# SN32F400 register map
Vendor: SONiX Technology Co., Ltd.; Series: SN32F400; File version: 1.1
CPU: CM0 r0p0, little endian, no MPU, no FPU, 2 interrupt priority bits
Registers are 32-bit, read-write, reset 0x0 unless marked. A register's access mark holds for its fields unless they carry their own. Offsets are from the block's base; [hi:lo] are bit positions; {n}, {i} and the like mark numbered series.

## SN_SPI0 — SPI0
Base 0x4001C000
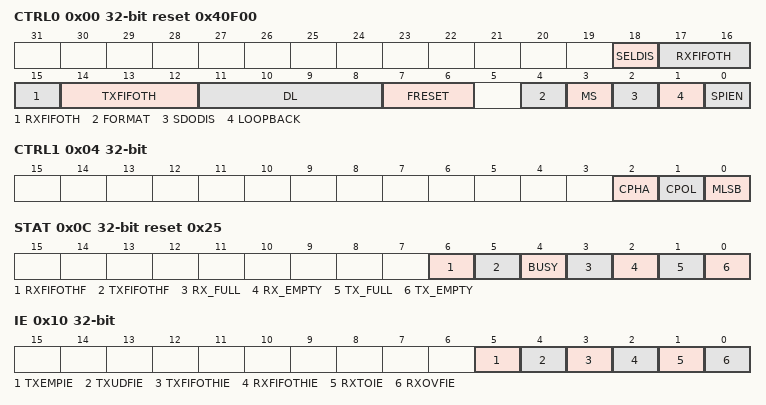
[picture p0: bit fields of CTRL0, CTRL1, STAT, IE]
0x00 CTRL0 reset 0x40F00 — Offset:0x00 SPIn Control register 0
  [18] SELDIS — Auto-SEL disable bit
    0=Enable Auto-SEL flow control; 1=Disable Auto-SEL flow control
  [17:15] RXFIFOTH — RX FIFO Threshold level
    {v}=LV{v} (RX FIFO threshold level is {v}) (v=0..7)
  [14:12] TXFIFOTH — TX FIFO Threshold level
    {v}=LV{v} (TX FIFO threshold level is {v}) (v=0..7)
  [11:8] DL — Data length = DL[3:0]+1
    {v}=Data length={v+1} (v=2..15)
  [7:6] FRESET wo — SPI FSM and FIFO Reset
    0=No effect; 3=Reset FSM and FIFO
  [4] FORMAT — Interface format
    0=SPI (SPI format)
  [3] MS — Master/Slave selection
    0=Master (Act as Master); 1=Slave (Act as Slave)
  [2] SDODIS — Slave data out disable
    0=Enable slave data out; 1=Disable (Diable slave data out (MISO=0))
  [1] LOOPBACK — Loopback mode enable
    0=Disable loopback mode; 1=Enable loopback mode
  [0] SPIEN — SPI enable
    0=Disable SPI; 1=Enable SPI
0x04 CTRL1 — Offset:0x04 SPIn Control register 1
  [2] CPHA — Clock phase of edge sampling
    0=The 1st bit is fixed already, and SCK 1st edge is to receive/transmit data; 1=SCK 1st edge is for data transition, and receive/transmit data at 2nd edge
  [1] CPOL — Clock priority selection
    0=Low (SCK idles at low level); 1=High (SCK idles at high level)
  [0] MLSB — MSB/LSB seletion
    0=MSB (MSB transmit first); 1=LSB (LSB transmit first)
0x08 CLKDIV — Offset:0x08 SPIn Clock Divider register
  [7:0] DIV — SPI0 SCK
0x0C STAT ro reset 0x25 — Offset:0x0C SPIn Status register
  [6] RXFIFOTHF — RX FIFO threshold flag
    0=Less equal (Data count in RX FIFO is less equal than RXFIFOTH); 1=More (Data count in RX FIFO is larger than RXFIFOTH)
  [5] TXFIFOTHF — TX FIFO threshold flag
    0=More (Data count in TX FIFO is larger than TXFIFOTH); 1=Less equal (Data count in TX FIFO is less equal than TXFIFOTH)
  [4] BUSY — Busy flag
    0=Idle (SSPn is idle); 1=Busy (SSPn is transfering)
  [3] RX_FULL — RX FIFO full flag
    0=None (RX FIFO is not full); 1=Full (RX FIFO is full)
  [2] RX_EMPTY — RX FIFO empty flag
    0=None (RX FIFO is not empty); 1=Empty (RX FIFO is empty)
  [1] TX_FULL — TX FIFO full flag
    0=None (TX FIFO is not full); 1=Full (TX FIFO is full)
  [0] TX_EMPTY — TX FIFO empty flag
    0=None (TX FIFO is not empty); 1=Empty (TX FIFO is empty)
0x10 IE — Offset:0x10 SPIn Interrupt Enable register
  [5] TXEMPIE — TX all empty interrupt enable
    0=Disable TX all empty interrupt; 1=Enable TX all empty interrupt
  [4] TXUDFIE — TX underflow interrupt enable
    0=Disable TX underflow interrupt; 1=Enable TX underflow interrupt
  [3] TXFIFOTHIE — TX FIFO threshold interrupt enable
    0=Disable TX FIFO threshold interrupt; 1=Enable TX FIFO threshold interrupt
  [2] RXFIFOTHIE — RX FIFO threshold interrupt enable
    0=Disable RX FIFO threshold interrupt; 1=Enable RX FIFO threshold interrupt
  [1] RXTOIE — RX time-out interrupt enable
    0=Disable RX time-out interrupt; 1=Enable RX time-out interrupt
  [0] RXOVFIE — RX FIFO overflow interrupt enable
    0=Disable RX FIFO overflow interrupt; 1=Enable RX FIFO overflow interrupt
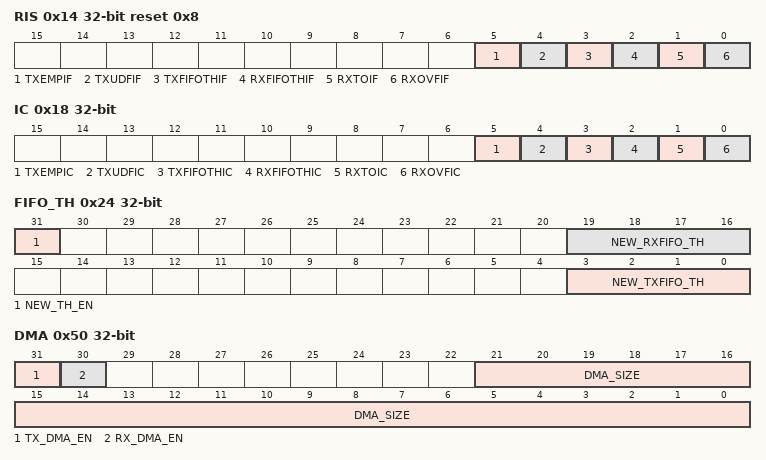
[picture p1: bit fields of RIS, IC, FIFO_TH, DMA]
0x14 RIS ro reset 0x8 — Offset:0x14 SPIn Raw Interrupt Status register
  [5] TXEMPIF — TX all empty interrupt flag
    0=No (No TX all empty interrupt); 1=All empty (TX all empty triggered)
  [4] TXUDFIF — TX underflow interrupt flag
    0=No (No TX underflow interrupt); 1=Underflow (TX underflow triggered)
  [3] TXFIFOTHIF — TX FIFO threshold interrupt flag
    0=No (No TXFIFOTH interrupt); 1=Met (TX FIFO threshold is triggered when TXFIFOTHIE=1)
  [2] RXFIFOTHIF — RX FIFO threshold interrupt flag
    0=No (No RXFIFOTH interrupt); 1=Met (RX FIFO threshold is triggered when RXFIFOTHIE=1)
  [1] RXTOIF — RX time-out interrupt flag
    0=No (No RXTO interrupt); 1=Met (RXTO interrupt is triggered when RXTOIE=1)
  [0] RXOVFIF — RX FIFO overflow interrupt flag
    0=No (No RXOVF interrupt); 1=Met (RXOVF interrupt is triggered when RXOVFIE=1)
0x18 IC wo — Offset:0x18 SPIn Interrupt Clear register
  [5] TXEMPIC — TX empty interrupt flag Clear
    0=None (No effect); 1=Clear TXEMPIF flag
  [4] TXUDFIC — TX underflow interrupt flag Clear
    0=None (No effect); 1=Clear TXUDIF flag
  [3] TXFIFOTHIC — TX Interrupt flag Clear
    0=None (No effect); 1=Clear TXFIFOTH flag
  [2] RXFIFOTHIC — RX Interrupt flag Clear
    0=None (No effect); 1=Clear RXFIFOTH flag
  [1] RXTOIC — RX time-out interrupt flag clear
    0=None (No effect); 1=Clear RXTO flag
  [0] RXOVFIC — RX FIFO overflow flag clear
    0=None (No effect); 1=Clear RXOVF flag
0x1C DATA — Offset:0x1C SPIn Data register
  [15:0] DATA — SPI Data
0x20 DFDLY — Offset:0x20 SPIn Data Fetch register
  [0] DF — SPI0 data fetch control bit
    0=Disable data fetch delay function; 1=Enable when SCKn frequency is higher than 6MHz
0x24 FIFO_TH — Offset:0x24 SPIn FIFO threshold register
  [31] NEW_TH_EN — Use new TX/RX threshold setting
    0=FIFO 8*half-word (TX/RX threshold setting is from TX/RXFIFOTH[2:0]); 1=FIFO 16*byte (TX/RX threshold setting is from NEW_TX/RXFIFO_TH[3:0])
  [19:16] NEW_RXFIFO_TH — RX FIFO Threshold level
  [3:0] NEW_TXFIFO_TH — TX FIFO Threshold level
0x50 DMA — Offset:0x50 SPIn DMA mode register
  [31] TX_DMA_EN — TX DMA enable
    0=Disable TX DMA mode; 1=Enable TX DMA mode
  [30] RX_DMA_EN — RX DMA enable
    0=Disable RX DMA mode; 1=Enable RX DMA mode
  [21:0] DMA_SIZE — Total DMA transfer bytes
0x58 ARGBCTRL — Offset:0x58 SPIn ARGB CTRL register
  [0] ARGBM — SPIn ARGB mode
    0=Disable ARGB mode; 1=Enable ARGB mode
